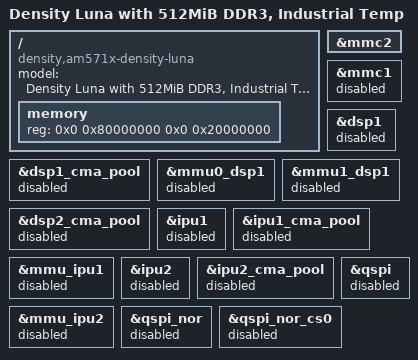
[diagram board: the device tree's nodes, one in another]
/*
 * Copyright (C) 2022 Density, Inc
 *
 */
/dts-v1/;

#include "dra72x.dtsi"

#include "am57xx-density-luna-io.dtsi"      /* Luna I/O - based on am572x-phycore-som.dtsi */
#include "am57xx-density-luna.dtsi"         /* Luna Base - based on am572x-ksp-5015.dtsi */
// #include "cmem-dra72x.dtsi"                 /* cmem for dsp/eve */

/ {
	model = "Density Luna with 512MiB DDR3, Industrial Temp";
	compatible = "density,am571x-density-luna", "ti,dra722", "ti,dra72", "ti,dra7";

	memory {
		device_type = "memory";
		reg = <0x0 0x80000000 0x0 0x20000000>; /* 512MiB */
	};
};

/* EMMC */
&mmc2 {
	status = "okay";
};

/* SD Card */
&mmc1 {
	status = "disabled";
};

/* DSP 1 */
&dsp1 {
	status = "disabled";
};

&dsp1_cma_pool {
	status = "disabled";
};

&mmu0_dsp1 {
	status = "disabled";
};

&mmu1_dsp1 {
	status = "disabled";
};

/* DSP 2 */
&dsp2_cma_pool {
	status = "disabled";
};

/* IPU 1 */
&ipu1 {
	status = "disabled";
};

&ipu1_cma_pool {
	status = "disabled";
};

&mmu_ipu1 {
	status = "disabled";
};

/* IPU 2 */
&ipu2 {
	status = "disabled";
};

&ipu2_cma_pool {
	status = "disabled";
};

&mmu_ipu2 {
	status = "disabled";
};

/* SPI */
&qspi {
	status = "disabled";
};

&qspi_nor {
	status = "disabled";
};

&qspi_nor_cs0 {
	status = "disabled";
};
